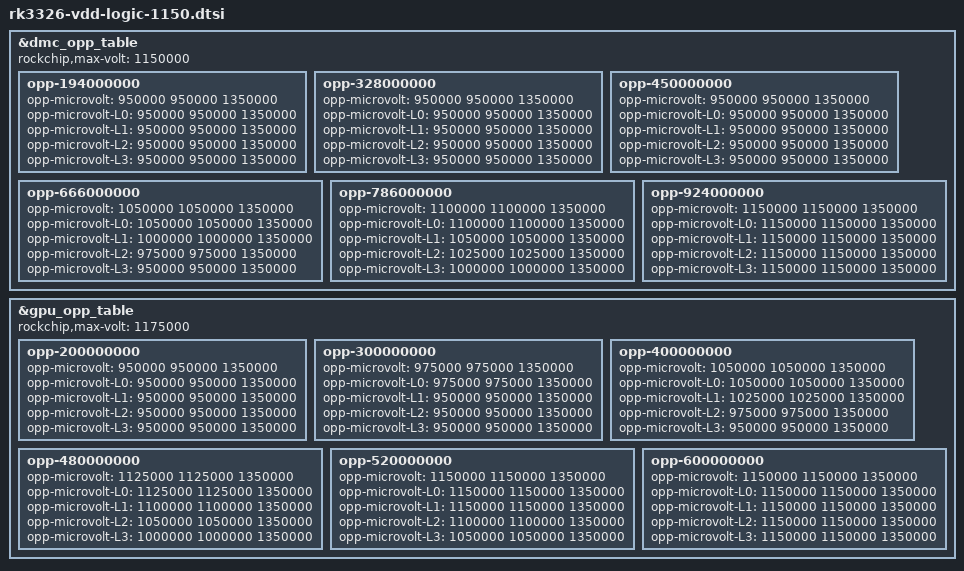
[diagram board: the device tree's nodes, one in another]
// SPDX-License-Identifier: (GPL-2.0+ OR MIT)
/*
 * DDR and GPU voltages for boards whose vdd_logic tops out at 1.15 V, as the
 * ArkOS 4.4 tree ran them. Include after rk3326-oc.dtsi.
 *
 * The flat 1.175 V tables used with the HG36 base's 1.175 V vdd_logic floor
 * exceed this regulator, which leaves no usable DDR OPP and drops the top GPU
 * OPPs. 1.032 GHz DDR needs 1.2 V and is usable only with rk3326-oc-voltage.
 *
 * The GPU and the DMC share vdd_logic. A single opp-microvolt value is an
 * exact request (min = target = max), so whenever the two ask for different
 * voltages the regulator core rejects one of them ("Restricting voltage")
 * and that DVFS step fails. Each entry is a <target min max> triplet with
 * the max at vdd_logic's limit instead, so the rail runs at the higher of
 * the two requests, as the 5.10 drivers did.
 */

&dmc_opp_table {
	rockchip,max-volt = <1150000>;

	opp-194000000 {
		opp-microvolt = <950000 950000 1350000>;
		opp-microvolt-L0 = <950000 950000 1350000>;
		opp-microvolt-L1 = <950000 950000 1350000>;
		opp-microvolt-L2 = <950000 950000 1350000>;
		opp-microvolt-L3 = <950000 950000 1350000>;
	};
	opp-328000000 {
		opp-microvolt = <950000 950000 1350000>;
		opp-microvolt-L0 = <950000 950000 1350000>;
		opp-microvolt-L1 = <950000 950000 1350000>;
		opp-microvolt-L2 = <950000 950000 1350000>;
		opp-microvolt-L3 = <950000 950000 1350000>;
	};
	opp-450000000 {
		opp-microvolt = <950000 950000 1350000>;
		opp-microvolt-L0 = <950000 950000 1350000>;
		opp-microvolt-L1 = <950000 950000 1350000>;
		opp-microvolt-L2 = <950000 950000 1350000>;
		opp-microvolt-L3 = <950000 950000 1350000>;
	};
	opp-666000000 {
		opp-microvolt = <1050000 1050000 1350000>;
		opp-microvolt-L0 = <1050000 1050000 1350000>;
		opp-microvolt-L1 = <1000000 1000000 1350000>;
		opp-microvolt-L2 = <975000 975000 1350000>;
		opp-microvolt-L3 = <950000 950000 1350000>;
	};
	opp-786000000 {
		opp-microvolt = <1100000 1100000 1350000>;
		opp-microvolt-L0 = <1100000 1100000 1350000>;
		opp-microvolt-L1 = <1050000 1050000 1350000>;
		opp-microvolt-L2 = <1025000 1025000 1350000>;
		opp-microvolt-L3 = <1000000 1000000 1350000>;
		status = "okay";
	};
	opp-924000000 {
		opp-microvolt = <1150000 1150000 1350000>;
		opp-microvolt-L0 = <1150000 1150000 1350000>;
		opp-microvolt-L1 = <1150000 1150000 1350000>;
		opp-microvolt-L2 = <1150000 1150000 1350000>;
		opp-microvolt-L3 = <1150000 1150000 1350000>;
	};
};

&gpu_opp_table {
	rockchip,max-volt = <1175000>;

	opp-200000000 {
		opp-microvolt = <950000 950000 1350000>;
		opp-microvolt-L0 = <950000 950000 1350000>;
		opp-microvolt-L1 = <950000 950000 1350000>;
		opp-microvolt-L2 = <950000 950000 1350000>;
		opp-microvolt-L3 = <950000 950000 1350000>;
	};
	opp-300000000 {
		opp-microvolt = <975000 975000 1350000>;
		opp-microvolt-L0 = <975000 975000 1350000>;
		opp-microvolt-L1 = <950000 950000 1350000>;
		opp-microvolt-L2 = <950000 950000 1350000>;
		opp-microvolt-L3 = <950000 950000 1350000>;
	};
	opp-400000000 {
		opp-microvolt = <1050000 1050000 1350000>;
		opp-microvolt-L0 = <1050000 1050000 1350000>;
		opp-microvolt-L1 = <1025000 1025000 1350000>;
		opp-microvolt-L2 = <975000 975000 1350000>;
		opp-microvolt-L3 = <950000 950000 1350000>;
	};
	opp-480000000 {
		opp-microvolt = <1125000 1125000 1350000>;
		opp-microvolt-L0 = <1125000 1125000 1350000>;
		opp-microvolt-L1 = <1100000 1100000 1350000>;
		opp-microvolt-L2 = <1050000 1050000 1350000>;
		opp-microvolt-L3 = <1000000 1000000 1350000>;
	};
	opp-520000000 {
		opp-microvolt = <1150000 1150000 1350000>;
		opp-microvolt-L0 = <1150000 1150000 1350000>;
		opp-microvolt-L1 = <1150000 1150000 1350000>;
		opp-microvolt-L2 = <1100000 1100000 1350000>;
		opp-microvolt-L3 = <1050000 1050000 1350000>;
	};
	opp-600000000 {
		opp-microvolt = <1150000 1150000 1350000>;
		opp-microvolt-L0 = <1150000 1150000 1350000>;
		opp-microvolt-L1 = <1150000 1150000 1350000>;
		opp-microvolt-L2 = <1150000 1150000 1350000>;
		opp-microvolt-L3 = <1150000 1150000 1350000>;
	};
};
